# TA2_356.0_inst2 register map
Vendor: Texas Instruments
Peripheral module from a debugger description file (folder msp430).
Registers are 16-bit, access not given, no defined reset value unless marked. A register's access mark holds for its fields unless they carry their own. Offsets are as the file gives them; lines under a group give offsets from that group; [hi:lo] are bit positions; {n}, {i} and the like mark numbered series; 'fields as' and 'values as' point back to an identical list; <NAME> marks a mode.

## TA2
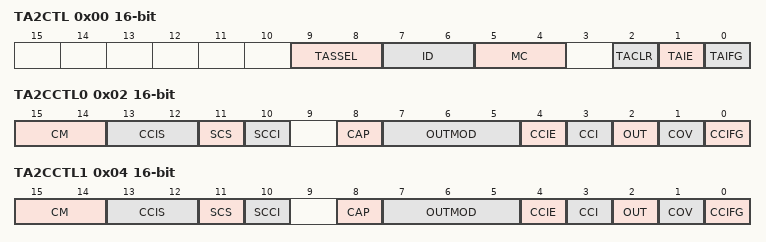
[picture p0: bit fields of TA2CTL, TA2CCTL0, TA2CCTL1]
0x00 TA2CTL rw — TimerAx Control Register
  [9:8] TASSEL — TimerA clock source select
    0=TACLK (TAxCLK); 1=ACLK; 2=SMCLK; 3=INCLK
  [7:6] ID — Input divider
    0=1; 1=2; 2=4; 3=8
  [5:4] MC — Mode control
    0=STOP (Stop mode: Timer is halted); 1=UP (Up mode: Timer counts up to TAxCCR0); 2=CONTINUOUS (Continuous mode: Timer counts up to 0FFFFh); 3=UPDOWN (Up/down mode: Timer counts up to TAxCCR0 then down to 0000h)
  [2] TACLR — TimerA clear
  [1] TAIE — TimerA interrupt enable
    0=Interrupt disabled; 1=Interrupt enabled
  [0] TAIFG — TimerA interrupt flag
    0=No interrupt pending; 1=Interrupt pending
0x02 TA2CCTL0 access per field — Timer_A Capture/Compare Control Register
  [15:14] CM rw — Capture mode
    0=NONE (No capture); 1=RISING (Capture on rising edge); 2=FALLING (Capture on falling edge); 3=BOTH (Capture on both rising and falling edges)
  [13:12] CCIS rw — Capture/compare input select
    0=CCIA (CCIxA); 1=CCIB (CCIxB); 2=GND; 3=VCC
  [11] SCS rw — Synchronize capture source
    0=ASYNC (Asynchronous capture); 1=SYNC (Synchronous capture)
  [10] SCCI rw — Synchronized capture/compare input
  [8] CAP rw — Capture mode
    0=COMPARE (Compare mode); 1=CAPTURE (Capture mode)
  [7:5] OUTMOD rw — Output mode
    0=OUT bit value; 1=Set; 2=Toggle/reset; 3=Set/reset; 4=Toggle; 5=Reset; 6=Toggle/set; 7=Reset/set
  [4] CCIE rw — Capture/compare interrupt enable
    0=Interrupt disabled; 1=Interrupt enabled
  [3] CCI ro — Capture/compare input
  [2] OUT rw — Output
    0=LOW (Output low); 1=HIGH (Output high)
  [1] COV rw — Capture overflow
    0=No capture overflow occurred; 1=Capture overflow occurred
  [0] CCIFG rw — Capture/compare interrupt flag
    0=No interrupt pending; 1=Interrupt pending
0x04 TA2CCTL1 access per field — Timer_A Capture/Compare Control Register
  fields as TA2CCTL0
0x10 TA2R — TimerA register
0x12 TA2CCR0 — Timer_A Capture/Compare Register
0x14 TA2CCR1 — Timer_A Capture/Compare Register
0x20 TA2EX0 rw — TimerAx Expansion 0 Register
  [2:0] TAIDEX — Input divider expansion
    {v}=Divide by {v+1} (v=0..7)
0x2E TA2IV ro — TimerAx Interrupt Vector Register
  [15:0] TAIV — TimerA interrupt vector value
    0=NONE (No interrupt pending); 2=TACCR1 (Interrupt Source: Capture/compare 1; Interrupt Flag: TAxCCR1 CCIFG; Interrupt Priority: Highest); 4=TACCR2 (Interrupt Source: Capture/compare 2; Interrupt Flag: TAxCCR2 CCIFG); 6=TACCR3 (Interrupt Source: Capture/compare 3; Interrupt Flag: TAxCCR3 CCIFG); 8=TACCR4 (Interrupt Source: Capture/compare 4; Interrupt Flag: TAxCCR4 CCIFG); 10=TACCR5 (Interrupt Source: Capture/compare 5; Interrupt Flag: TAxCCR5 CCIFG); 12=TACCR6 (Interrupt Source: Capture/compare 6; Interrupt Flag: TAxCCR6 CCIFG); 14=TAIFG (Interrupt Source: Timer overflow; Interrupt Flag: TAxCTL TAIFG; Interrupt Priority: Lowest)
